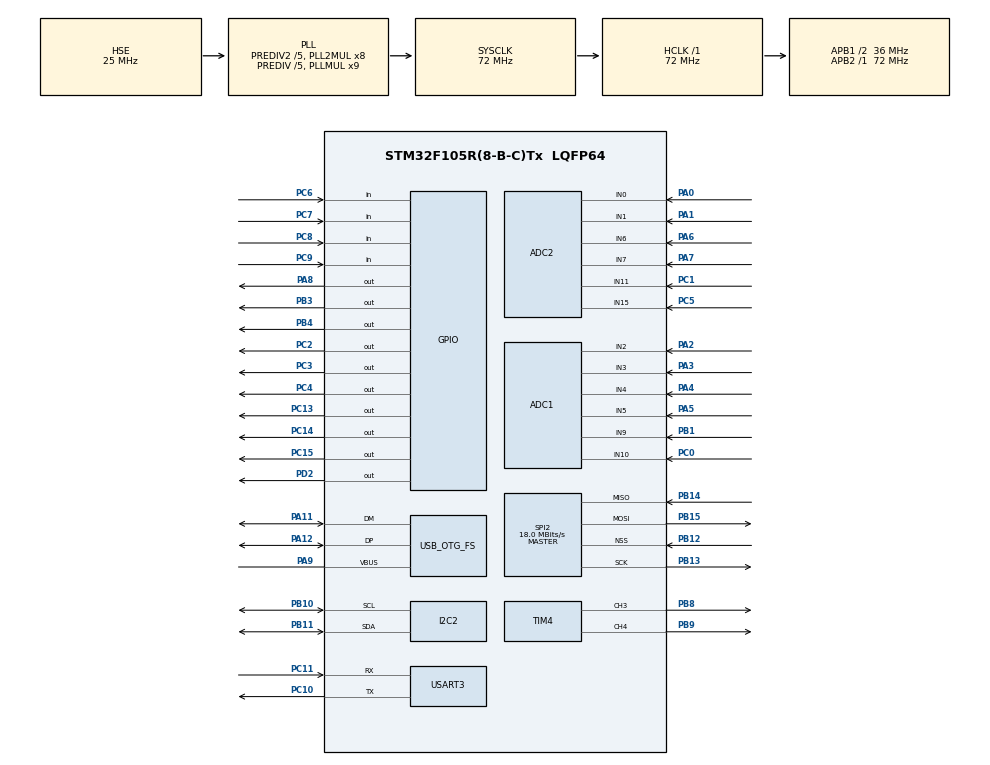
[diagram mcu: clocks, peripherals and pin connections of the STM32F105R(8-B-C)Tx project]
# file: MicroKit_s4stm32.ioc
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ADC1.Channel-4\#ChannelRegularConversion=ADC_CHANNEL_3
ADC1.ContinuousConvMode=ENABLE
ADC1.NbrOfConversion=1
ADC1.NbrOfConversionFlag=1
ADC1.Rank-4\#ChannelRegularConversion=1
ADC1.SamplingTime-4\#ChannelRegularConversion=ADC_SAMPLETIME_1CYCLE_5
ADC1.master=1
ADC2.Channel-25\#ChannelRegularConversion=ADC_CHANNEL_0
ADC2.ContinuousConvMode=ENABLE
ADC2.NbrOfConversionFlag=1
ADC2.Rank-25\#ChannelRegularConversion=1
ADC2.SamplingTime-25\#ChannelRegularConversion=ADC_SAMPLETIME_1CYCLE_5
Mcu.Family=STM32F1
Mcu.Name=STM32F105R(8-B-C)Tx
Mcu.Package=LQFP64
NVIC.ADC1_2_IRQn=true\:0\:0\:true\:false\:true
NVIC.I2C2_EV_IRQn=true\:1\:0\:true\:false\:true
NVIC.OTG_FS_IRQn=true\:0\:0\:true\:false\:true
NVIC.PriorityGroup=NVIC_PRIORITYGROUP_4
PA0-WKUP.Signal=ADCx_IN0
PA1.Signal=ADCx_IN1
PA11.Mode=Device_Only
PA11.Signal=USB_OTG_FS_DM
PA12.Mode=Device_Only
PA12.Signal=USB_OTG_FS_DP
PA2.Signal=ADCx_IN2
PA3.Signal=ADCx_IN3
PA4.Signal=ADCx_IN4
PA5.Signal=ADCx_IN5
PA6.Signal=ADCx_IN6
PA7.Signal=ADCx_IN7
PA8.Signal=GPIO_Output
PA9.Mode=Activate_VBUS
PA9.Signal=USB_OTG_FS_VBUS
PB1.Signal=ADCx_IN9
PB10.Mode=I2C
PB10.Signal=I2C2_SCL
PB11.Mode=I2C
PB11.Signal=I2C2_SDA
PB12.Mode=NSS_Signal_Hard_Input
PB12.Signal=SPI2_NSS
PB13.Mode=Full_Duplex_Master
PB13.Signal=SPI2_SCK
PB14.Mode=Full_Duplex_Master
PB14.Signal=SPI2_MISO
PB15.Mode=Full_Duplex_Master
PB15.Signal=SPI2_MOSI
PB3.PinState=GPIO_PIN_SET
PB3.Signal=GPIO_Output
PB4.PinState=GPIO_PIN_SET
PB4.Signal=GPIO_Output
PB8.Signal=S_TIM4_CH3
PB9.Signal=S_TIM4_CH4
PC0.Signal=ADCx_IN10
PC1.Signal=ADCx_IN11
PC10.Mode=Asynchronous
PC10.Signal=USART3_TX
PC11.Mode=Asynchronous
PC11.Signal=USART3_RX
PC13-TAMPER-RTC.Signal=GPIO_Output
PC14-OSC32_IN.Signal=GPIO_Output
PC15-OSC32_OUT.Signal=GPIO_Output
PC2.Signal=GPIO_Output
PC3.Signal=GPIO_Output
PC4.Signal=GPIO_Output
PC5.Signal=ADCx_IN15
PC6.Signal=GPIO_Input
PC7.Signal=GPIO_Input
PC8.Signal=GPIO_Input
PC9.Signal=GPIO_Input
PD0-OSC_IN.Mode=HSE-External-Oscillator
PD0-OSC_IN.Signal=RCC_OSC_IN
PD1-OSC_OUT.Mode=HSE-External-Oscillator
PD1-OSC_OUT.Signal=RCC_OSC_OUT
PD2.Signal=GPIO_Output
ProjectManager.HeapSize=0x200
ProjectManager.StackSize=0x400
ProjectManager.TargetToolchain=SW4STM32
RCC.ADCPresc=RCC_ADCPCLK2_DIV6
RCC.AHBFreq_Value=72000000
RCC.APB1CLKDivider=RCC_HCLK_DIV2
RCC.APB1Freq_Value=36000000
RCC.APB1TimFreq_Value=72000000
RCC.APB2Freq_Value=72000000
RCC.APB2TimFreq_Value=72000000
RCC.HCLKFreq_Value=72000000
RCC.HSEDivPLL=RCC_HSE_PREDIV_DIV5
RCC.HSE_VALUE=25000000
RCC.HSIState=RCC_HSI_ON
RCC.PLLMUL=RCC_PLL_MUL9
RCC.Prediv1Source=RCC_PREDIV1_SOURCE_PLL2
RCC.Prediv2=RCC_HSE_PREDIV2_DIV5
RCC.SYSCLKFreq_VALUE=72000000
RCC.SYSCLKSource=RCC_SYSCLKSOURCE_PLLCLK
RCC.USBFreq_Value=48000000
SH.ADCx_IN0.0=ADC2_IN0,IN0
SH.ADCx_IN1.0=ADC2_IN1,IN1
SH.ADCx_IN10.0=ADC1_IN10,IN10
SH.ADCx_IN11.0=ADC2_IN11,IN11
SH.ADCx_IN15.0=ADC2_IN15,IN15
SH.ADCx_IN2.0=ADC1_IN2,IN2
SH.ADCx_IN3.0=ADC1_IN3,IN3
SH.ADCx_IN4.0=ADC1_IN4,IN4
SH.ADCx_IN5.0=ADC1_IN5,IN5
SH.ADCx_IN6.0=ADC2_IN6,IN6
SH.ADCx_IN7.0=ADC2_IN7,IN7
SH.ADCx_IN9.0=ADC1_IN9,IN9
SH.S_TIM4_CH3.0=TIM4_CH3,PWM Generation3 CH3
SH.S_TIM4_CH4.0=TIM4_CH4,PWM Generation4 CH4
SPI2.BaudRatePrescaler=SPI_BAUDRATEPRESCALER_2
SPI2.CalculateBaudRate=18.0 MBits/s
SPI2.Mode=SPI_MODE_MASTER
SPI2.VirtualNSS=VM_NSSHARD
TIM4.Channel-PWM\ Generation3\ CH3=TIM_CHANNEL_3
TIM4.Channel-PWM\ Generation4\ CH4=TIM_CHANNEL_4
USB_DEVICE.CLASS_NAME_FS=CDC
USB_DEVICE.MANUFACTURER_STRING=Lab Adaptive
USB_DEVICE.USBD_HandleTypeDef=hUsbDeviceFS
USB_DEVICE.VirtualMode=Cdc
USB_DEVICE.VirtualModeFS=Cdc_FS
USB_OTG_FS.VirtualMode=Device_Only
VP_TIM4_VS_ClockSourceINT.Mode=Internal
VP_USB_DEVICE_VS_USB_DEVICE_CDC_FS.Mode=CDC_FS
board=MicroKit_s4stm32

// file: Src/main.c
/**
  ******************************************************************************
  * File Name          : main.c
  * Description        : Main program body
  ******************************************************************************
  *
  * COPYRIGHT(c) 2016 STMicroelectronics
  *
  * Redistribution and use in source and binary forms, with or without modification,
  * are permitted provided that the following conditions are met:
  *   1. Redistributions of source code must retain the above copyright notice,
  *      this list of conditions and the following disclaimer.
  *   2. Redistributions in binary form must reproduce the above copyright notice,
  *      this list of conditions and the following disclaimer in the documentation
  *      and/or other materials provided with the distribution.
  *   3. Neither the name of STMicroelectronics nor the names of its contributors
  *      may be used to endorse or promote products derived from this software
  *      without specific prior written permission.
  *
  * THIS SOFTWARE IS PROVIDED BY THE COPYRIGHT HOLDERS AND CONTRIBUTORS "AS IS"
  * AND ANY EXPRESS OR IMPLIED WARRANTIES, INCLUDING, BUT NOT LIMITED TO, THE
  * IMPLIED WARRANTIES OF MERCHANTABILITY AND FITNESS FOR A PARTICULAR PURPOSE ARE
  * DISCLAIMED. IN NO EVENT SHALL THE COPYRIGHT HOLDER OR CONTRIBUTORS BE LIABLE
  * FOR ANY DIRECT, INDIRECT, INCIDENTAL, SPECIAL, EXEMPLARY, OR CONSEQUENTIAL
  * DAMAGES (INCLUDING, BUT NOT LIMITED TO, PROCUREMENT OF SUBSTITUTE GOODS OR
  * SERVICES; LOSS OF USE, DATA, OR PROFITS; OR BUSINESS INTERRUPTION) HOWEVER
  * CAUSED AND ON ANY THEORY OF LIABILITY, WHETHER IN CONTRACT, STRICT LIABILITY,
  * OR TORT (INCLUDING NEGLIGENCE OR OTHERWISE) ARISING IN ANY WAY OUT OF THE USE
  * OF THIS SOFTWARE, EVEN IF ADVISED OF THE POSSIBILITY OF SUCH DAMAGE.
  *
  ******************************************************************************
  */
#include "stm32f1xx_hal.h"
#include "adc.h"
#include "i2c.h"
#include "spi.h"
#include "tim.h"
#include "usart.h"
#include "usb_device.h"
#include "gpio.h"

/* USER CODE BEGIN PV */
/* Private variables ---------------------------------------------------------*/

/* USER CODE END PV */

void SystemClock_Config(void);

/* USER CODE BEGIN PFP */
/* Private function prototypes -----------------------------------------------*/

/* USER CODE END PFP */

int main(void)
{

  /* MCU Configuration----------------------------------------------------------*/

  /* Reset of all peripherals, Initializes the Flash interface and the Systick. */
  HAL_Init();

  /* Configure the system clock */
  SystemClock_Config();

  /* Initialize all configured peripherals */
  MX_GPIO_Init();
  MX_ADC1_Init();
  MX_ADC2_Init();
  MX_I2C2_Init();
  MX_SPI2_Init();
  MX_TIM4_Init();
  MX_USART3_UART_Init();
  MX_USB_DEVICE_Init();

  /* Infinite loop */
  /* USER CODE BEGIN WHILE */
  HAL_GPIO_WritePin(GPIOB, GPIO_PIN_3|GPIO_PIN_4, GPIO_PIN_SET);
  while (1)
  {
  /* USER CODE END WHILE */

  }

}

/** System Clock Configuration
*/
void SystemClock_Config(void)
{

  RCC_OscInitTypeDef RCC_OscInitStruct;
  RCC_ClkInitTypeDef RCC_ClkInitStruct;
  RCC_PeriphCLKInitTypeDef PeriphClkInit;

  RCC_OscInitStruct.OscillatorType = RCC_OSCILLATORTYPE_HSE;
  RCC_OscInitStruct.HSEState = RCC_HSE_ON;
  RCC_OscInitStruct.HSEPredivValue = RCC_HSE_PREDIV_DIV5;
  RCC_OscInitStruct.Prediv1Source = RCC_PREDIV1_SOURCE_PLL2;
  RCC_OscInitStruct.PLL.PLLState = RCC_PLL_ON;
  RCC_OscInitStruct.PLL.PLLSource = RCC_PLLSOURCE_HSE;
  RCC_OscInitStruct.PLL.PLLMUL = RCC_PLL_MUL9;
  RCC_OscInitStruct.PLL2.PLL2State = RCC_PLL2_ON;
  RCC_OscInitStruct.PLL2.PLL2MUL = RCC_PLL2_MUL8;
  RCC_OscInitStruct.PLL2.HSEPrediv2Value = RCC_HSE_PREDIV2_DIV5;
  HAL_RCC_OscConfig(&RCC_OscInitStruct);

  RCC_ClkInitStruct.ClockType = RCC_CLOCKTYPE_HCLK|RCC_CLOCKTYPE_SYSCLK
                              |RCC_CLOCKTYPE_PCLK1|RCC_CLOCKTYPE_PCLK2;
  RCC_ClkInitStruct.SYSCLKSource = RCC_SYSCLKSOURCE_PLLCLK;
  RCC_ClkInitStruct.AHBCLKDivider = RCC_SYSCLK_DIV1;
  RCC_ClkInitStruct.APB1CLKDivider = RCC_HCLK_DIV2;
  RCC_ClkInitStruct.APB2CLKDivider = RCC_HCLK_DIV1;
  HAL_RCC_ClockConfig(&RCC_ClkInitStruct, FLASH_LATENCY_2);

  PeriphClkInit.PeriphClockSelection = RCC_PERIPHCLK_ADC|RCC_PERIPHCLK_USB;
  PeriphClkInit.AdcClockSelection = RCC_ADCPCLK2_DIV6;
  PeriphClkInit.UsbClockSelection = RCC_USBCLKSOURCE_PLL_DIV3;
  HAL_RCCEx_PeriphCLKConfig(&PeriphClkInit);

  HAL_SYSTICK_Config(HAL_RCC_GetHCLKFreq()/1000);

  HAL_SYSTICK_CLKSourceConfig(SYSTICK_CLKSOURCE_HCLK);

  __HAL_RCC_PLLI2S_ENABLE();

  /* SysTick_IRQn interrupt configuration */
  HAL_NVIC_SetPriority(SysTick_IRQn, 0, 0);
}

/************************ (C) COPYRIGHT STMicroelectronics *****END OF FILE****/
